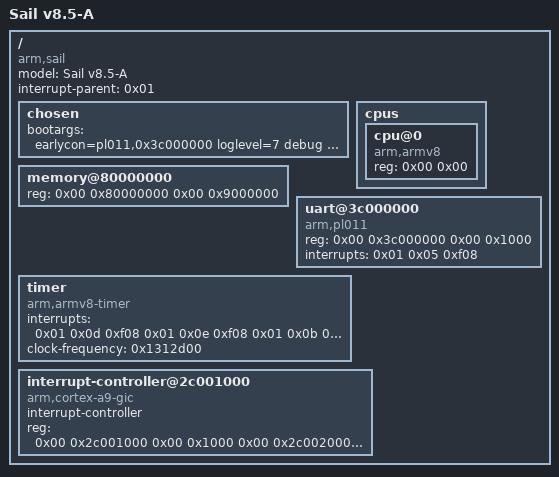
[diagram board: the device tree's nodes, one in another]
/dts-v1/;

/ {
	model = "Sail v8.5-A";
	compatible = "arm,sail";
	interrupt-parent = <0x01>;
	#address-cells = <0x02>;
	#size-cells = <0x02>;

	chosen {
		bootargs = "earlycon=pl011,0x3c000000 loglevel=7 debug acpi=off sched_debug keep_bootcon nohlt";
	};

	cpus {
		#address-cells = <0x02>;
		#size-cells = <0x00>;

		cpu@0 {
			device_type = "cpu";
			compatible = "arm,armv8";
			reg = <0x00 0x00>;
		};
	};

	memory@80000000 {
		device_type = "memory";
		reg = <0x00 0x80000000 0x00 0x9000000>;
	};

	uart@3c000000 {
		compatible = "arm,pl011\0arm,primecell";
		reg = <0x00 0x3c000000 0x00 0x1000>;
		interrupts = <0x01 0x05 0xf08>;
	};

	timer {
		compatible = "arm,armv8-timer";
		interrupts = <0x01 0x0d 0xf08 0x01 0x0e 0xf08 0x01 0x0b 0xf08 0x01 0x0a 0xf08>;
		clock-frequency = <0x1312d00>;
	};

	interrupt-controller@2c001000 {
		compatible = "arm,cortex-a9-gic";
		#interrupt-cells = <0x03>;
		#address-cells = <0x02>;
		interrupt-controller;
		reg = <0x00 0x2c001000 0x00 0x1000 0x00 0x2c002000 0x00 0x2000>;
		phandle = <0x01>;
	};
};
